AUTOSAR XML (schema 4-2-2)
package /STELLANTIS/EPT/ASWCs
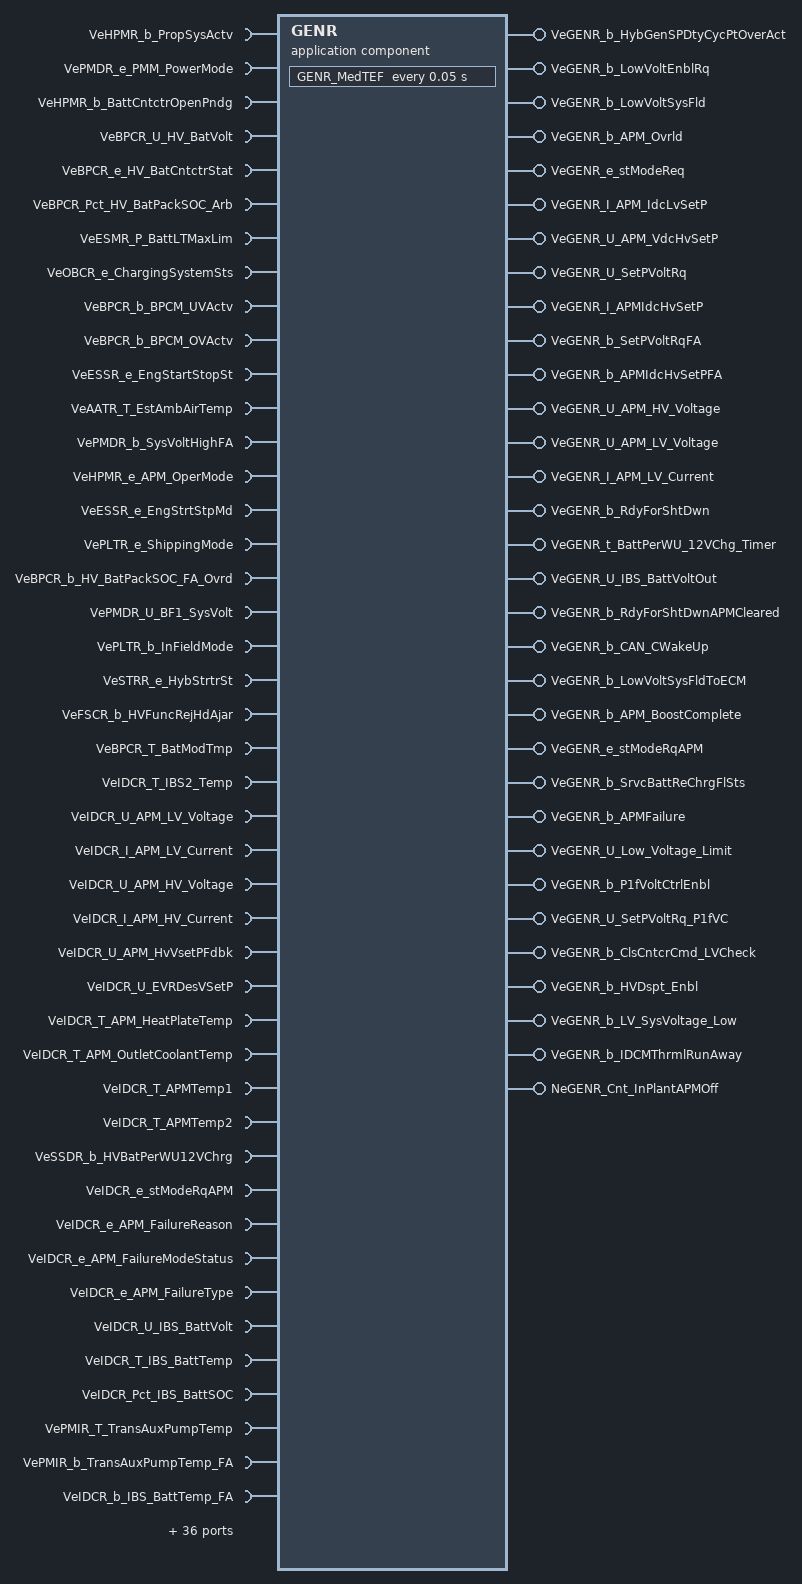
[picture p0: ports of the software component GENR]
  application sw component type GENR
    79 x require port:
      VeHPMR_b_PropSysActv: nonqueued-receiver-com-spec{data-element=Value, init-value=0}, required-interface=VeHPMR_b_PropSysActv
      VePMDR_e_PMM_PowerMode: nonqueued-receiver-com-spec{data-element=Value, init-value=CePMDR_e_PowerMode_Off}, required-interface=VePMDR_e_PMM_PowerMode
      VeHPMR_b_BattCntctrOpenPndg: nonqueued-receiver-com-spec{data-element=Value, init-value=0}, required-interface=VeHPMR_b_BattCntctrOpenPndg
      VeBPCR_U_HV_BatVolt: nonqueued-receiver-com-spec{data-element=Value, init-value=0}, required-interface=VeBPCR_U_HV_BatVolt
      VeBPCR_e_HV_BatCntctrStat: nonqueued-receiver-com-spec{data-element=Value, init-value=CeHVTR_e_Open}, required-interface=VeBPCR_e_HV_BatCntctrStat
      VeBPCR_Pct_HV_BatPackSOC_Arb: nonqueued-receiver-com-spec{data-element=Value, init-value=0}, required-interface=VeBPCR_Pct_HV_BatPackSOC_Arb
      VeESMR_P_BattLTMaxLim: nonqueued-receiver-com-spec{data-element=Value, init-value=0}, required-interface=VeESMR_P_BattLTMaxLim
      VeOBCR_e_ChargingSystemSts: nonqueued-receiver-com-spec{data-element=Value, init-value=CeOBCR_e_NotCharging}, required-interface=VeOBCR_e_ChargingSystemSts
      VeBPCR_b_BPCM_UVActv: nonqueued-receiver-com-spec{data-element=Value, init-value=0}, required-interface=VeBPCR_b_BPCM_UVActv
      VeBPCR_b_BPCM_OVActv: nonqueued-receiver-com-spec{data-element=Value, init-value=0}, required-interface=VeBPCR_b_BPCM_OVActv
      VeESSR_e_EngStartStopSt: nonqueued-receiver-com-spec{data-element=Value, init-value=CeESSR_e_EngOff}, required-interface=VeESSR_e_EngStartStopSt
      VeAATR_T_EstAmbAirTemp: nonqueued-receiver-com-spec{data-element=Value, init-value=0}, required-interface=VeAATR_T_EstAmbAirTemp
      VePMDR_b_SysVoltHighFA: nonqueued-receiver-com-spec{data-element=Value, init-value=0}, required-interface=VePMDR_b_SysVoltHighFA
      VeHPMR_e_APM_OperMode: nonqueued-receiver-com-spec{data-element=Value, init-value=CeHPMR_e_Idle}, required-interface=VeHPMR_e_APM_OperMode
      VeESSR_e_EngStrtStpMd: nonqueued-receiver-com-spec{data-element=Value, init-value=CeESSR_e_Stop}, required-interface=VeESSR_e_EngStrtStpMd
      VePLTR_e_ShippingMode: nonqueued-receiver-com-spec{data-element=Value, init-value=CePLTR_e_ShipingMode_CUST_MD}, required-interface=VePLTR_e_ShippingMode
      VeBPCR_b_HV_BatPackSOC_FA_Ovrd: nonqueued-receiver-com-spec{data-element=Value, init-value=0}, required-interface=VeBPCR_b_HV_BatPackSOC_FA_Ovrd
      VePMDR_U_BF1_SysVolt: nonqueued-receiver-com-spec{data-element=Value, init-value=0}, required-interface=VePMDR_U_BF1_SysVolt
      VePLTR_b_InFieldMode: nonqueued-receiver-com-spec{data-element=Value, init-value=0}, required-interface=VePLTR_b_InFieldMode
      VeSTRR_e_HybStrtrSt: nonqueued-receiver-com-spec{data-element=Value, init-value=CeSTRR_e_KeyOffSt}, required-interface=VeSTRR_e_HybStrtrSt
      VeFSCR_b_HVFuncRejHdAjar: nonqueued-receiver-com-spec{data-element=Value, init-value=0}, required-interface=VeFSCR_b_HVFuncRejHdAjar
      VeBPCR_T_BatModTmp: nonqueued-receiver-com-spec{data-element=Value, init-value=0}, required-interface=VeBPCR_T_BatModTmp
      VeIDCR_T_IBS2_Temp: nonqueued-receiver-com-spec{data-element=Value, init-value=0}, required-interface=VeIDCR_T_IBS2_Temp
      VeIDCR_U_APM_LV_Voltage: nonqueued-receiver-com-spec{data-element=Value, init-value=0}, required-interface=VeIDCR_U_APM_LV_Voltage
      VeIDCR_I_APM_LV_Current: nonqueued-receiver-com-spec{data-element=Value, init-value=0}, required-interface=VeIDCR_I_APM_LV_Current
      VeIDCR_U_APM_HV_Voltage: nonqueued-receiver-com-spec{data-element=Value, init-value=0}, required-interface=VeIDCR_U_APM_HV_Voltage
      VeIDCR_I_APM_HV_Current: nonqueued-receiver-com-spec{data-element=Value, init-value=0}, required-interface=VeIDCR_I_APM_HV_Current
      VeIDCR_U_APM_HvVsetPFdbk: nonqueued-receiver-com-spec{data-element=Value, init-value=0}, required-interface=VeIDCR_U_APM_HvVsetPFdbk
      VeIDCR_U_EVRDesVSetP: nonqueued-receiver-com-spec{data-element=Value, init-value=0}, required-interface=VeIDCR_U_EVRDesVSetP
      VeIDCR_T_APM_HeatPlateTemp: nonqueued-receiver-com-spec{data-element=Value, init-value=0}, required-interface=VeIDCR_T_APM_HeatPlateTemp
      VeIDCR_T_APM_OutletCoolantTemp: nonqueued-receiver-com-spec{data-element=Value, init-value=0}, required-interface=VeIDCR_T_APM_OutletCoolantTemp
      VeIDCR_T_APMTemp1: nonqueued-receiver-com-spec{data-element=Value, init-value=0}, required-interface=VeIDCR_T_APMTemp1
      VeIDCR_T_APMTemp2: nonqueued-receiver-com-spec{data-element=Value, init-value=0}, required-interface=VeIDCR_T_APMTemp2
      VeSSDR_b_HVBatPerWU12VChrg: nonqueued-receiver-com-spec{data-element=Value, init-value=0}, required-interface=VeSSDR_b_HVBatPerWU12VChrg
      VeIDCR_e_stModeRqAPM: nonqueued-receiver-com-spec{data-element=Value, init-value=CeGENR_e_Default}, required-interface=VeIDCR_e_stModeRqAPM
      VeIDCR_e_APM_FailureReason: nonqueued-receiver-com-spec{data-element=Value, init-value=CeGENR_e_NoFailure}, required-interface=VeIDCR_e_APM_FailureReason
      VeIDCR_e_APM_FailureModeStatus: nonqueued-receiver-com-spec{data-element=Value, init-value=CeGENR_e_NoFailure}, required-interface=VeIDCR_e_APM_FailureModeStatus
      VeIDCR_e_APM_FailureType: nonqueued-receiver-com-spec{data-element=Value, init-value=CeGENR_e_FailureType_NoFailure}, required-interface=VeIDCR_e_APM_FailureType
      VeIDCR_U_IBS_BattVolt: nonqueued-receiver-com-spec{data-element=Value, init-value=0}, required-interface=VeIDCR_U_IBS_BattVolt
      VeIDCR_T_IBS_BattTemp: nonqueued-receiver-com-spec{data-element=Value, init-value=0}, required-interface=VeIDCR_T_IBS_BattTemp
      VeIDCR_Pct_IBS_BattSOC: nonqueued-receiver-com-spec{data-element=Value, init-value=0}, required-interface=VeIDCR_Pct_IBS_BattSOC
      VePMIR_T_TransAuxPumpTemp: nonqueued-receiver-com-spec{data-element=Value, init-value=0}, required-interface=VePMIR_T_TransAuxPumpTemp
      VePMIR_b_TransAuxPumpTemp_FA: nonqueued-receiver-com-spec{data-element=Value, init-value=0}, required-interface=VePMIR_b_TransAuxPumpTemp_FA
      VeIDCR_b_IBS_BattTemp_FA: nonqueued-receiver-com-spec{data-element=Value, init-value=0}, required-interface=VeIDCR_b_IBS_BattTemp_FA
      VeIDCR_e_IBS_BattTempFailSts: nonqueued-receiver-com-spec{data-element=Value, init-value=CeGENR_e_BattTempSts_Fail_NtPrsnt}, required-interface=VeIDCR_e_IBS_BattTempFailSts
      VeIDCR_b_IBS_BattTemp_SgnlRcvd: nonqueued-receiver-com-spec{data-element=Value, init-value=0}, required-interface=VeIDCR_b_IBS_BattTemp_SgnlRcvd
      VeIDCR_b_APM_HvVsetPFdbk_FA: nonqueued-receiver-com-spec{data-element=Value, init-value=0}, required-interface=VeIDCR_b_APM_HvVsetPFdbk_FA
      VeIDCR_b_IBS_BattSOC_FA: nonqueued-receiver-com-spec{data-element=Value, init-value=0}, required-interface=VeIDCR_b_IBS_BattSOC_FA
      VeIDCR_b_IBS_BattVolt_FA: nonqueued-receiver-com-spec{data-element=Value, init-value=0}, required-interface=VeIDCR_b_IBS_BattVolt_FA
      VeINVR_e_MtrA_InvrtrSt: nonqueued-receiver-com-spec{data-element=Value, init-value=CeINVR_e_NormalPowerStageOff}, required-interface=VeINVR_e_MtrA_InvrtrSt
      VeIDCR_e_DVC_APMSts: nonqueued-receiver-com-spec{data-element=Value, init-value=CeODCR_e_Return_ECU_Cntrl}, required-interface=VeIDCR_e_DVC_APMSts
      VeIDCR_y_APMSts: nonqueued-receiver-com-spec{data-element=Value, init-value=0}, required-interface=VeIDCR_y_APMSts
      VeIDCR_Pct_UtilPctOfDCDC: nonqueued-receiver-com-spec{data-element=Value, init-value=0}, required-interface=VeIDCR_Pct_UtilPctOfDCDC
      VeIDCR_e_APM_DeratingModeStatus: nonqueued-receiver-com-spec{data-element=Value, init-value=CeGENR_e_No_Derating}, required-interface=VeIDCR_e_APM_DeratingModeStatus
      VeIDCR_P_APM_OutputPwr: nonqueued-receiver-com-spec{data-element=Value, init-value=0}, required-interface=VeIDCR_P_APM_OutputPwr
      VeIDCR_P_APM_DeratePwr: nonqueued-receiver-com-spec{data-element=Value, init-value=0}, required-interface=VeIDCR_P_APM_DeratePwr
      VeIDCR_b_IBS_I_Batt_SgnlRcvd: nonqueued-receiver-com-spec{data-element=Value, init-value=0}, required-interface=VeIDCR_b_IBS_I_Batt_SgnlRcvd
      VeINVR_b_P1_CAN_COM_Error: nonqueued-receiver-com-spec{data-element=Value, init-value=0}, required-interface=VeINVR_b_P1_CAN_COM_Error
      VeBPCR_b_HVBatCntrWeld_ImpdOpn: nonqueued-receiver-com-spec{data-element=Value, init-value=0}, required-interface=VeBPCR_b_HVBatCntrWeld_ImpdOpn
      VeSRAR_b_OpnBattCntctr: nonqueued-receiver-com-spec{data-element=Value, init-value=0}, required-interface=VeSRAR_b_OpnBattCntctr
      VeIDCR_I_IBS_I_Converted: nonqueued-receiver-com-spec{data-element=Value, init-value=0}, required-interface=VeIDCR_I_IBS_I_Converted
      VeIDCR_b_IBS_I_Converted_FA: nonqueued-receiver-com-spec{data-element=Value, init-value=0}, required-interface=VeIDCR_b_IBS_I_Converted_FA
      VeFSCR_Pct_RadFanCmd: nonqueued-receiver-com-spec{data-element=Value, init-value=0}, required-interface=VeFSCR_Pct_RadFanCmd
      VeTAIR_Pct_FrtBlwrCmd: nonqueued-receiver-com-spec{data-element=Value, init-value=0}, required-interface=VeTAIR_Pct_FrtBlwrCmd
      VePMDR_U_BF2_SysVolt: nonqueued-receiver-com-spec{data-element=Value, init-value=0}, required-interface=VePMDR_U_BF2_SysVolt
      VeDMAB_y_StatusByte_InvData_APM: nonqueued-receiver-com-spec{data-element=Value, init-value=0}, required-interface=VeDMAB_y_StatusByte_InvData_APM
      VeDMAB_y_StatusByte_InvData_IDCM_CANC11: nonqueued-receiver-com-spec{data-element=Value, init-value=0}, required-interface=VeDMAB_y_StatusByte_InvData_IDCM_CANC11
      VeDMAB_y_StatusByte_InvData_IDCM: nonqueued-receiver-com-spec{data-element=Value, init-value=0}, required-interface=VeDMAB_y_StatusByte_InvData_IDCM
      VeDMAB_y_StatusByte_LosCommBECM_A: nonqueued-receiver-com-spec{data-element=Value, init-value=0}, required-interface=VeDMAB_y_StatusByte_LosCommBECM_A
      VeDMAB_y_StatusByte_LostCommBCM: nonqueued-receiver-com-spec{data-element=Value, init-value=0}, required-interface=VeDMAB_y_StatusByte_LostCommBCM
      VeDMAB_y_StatusByte_LostCommDCDC: nonqueued-receiver-com-spec{data-element=Value, init-value=0}, required-interface=VeDMAB_y_StatusByte_LostCommDCDC
      VeDMAB_y_StatusByte_LostCommIDCM: nonqueued-receiver-com-spec{data-element=Value, init-value=0}, required-interface=VeDMAB_y_StatusByte_LostCommIDCM
      VeDMAB_y_StatusByte_LostComm_IDCM_CANC11: nonqueued-receiver-com-spec{data-element=Value, init-value=0}, required-interface=VeDMAB_y_StatusByte_LostComm_IDCM_CANC11
      VeDMAB_y_StatusByte_HiSpdCANCommBus: nonqueued-receiver-com-spec{data-element=Value, init-value=0}, required-interface=VeDMAB_y_StatusByte_HiSpdCANCommBus
      VeDMAB_y_StatusByte_CommBus_B_Off: nonqueued-receiver-com-spec{data-element=Value, init-value=0}, required-interface=VeDMAB_y_StatusByte_CommBus_B_Off
      VeDMAB_y_StatusByte_InvData_SGCM: nonqueued-receiver-com-spec{data-element=Value, init-value=0}, required-interface=VeDMAB_y_StatusByte_InvData_SGCM
      VeDMAB_y_StatusByte_LostCommSGCM: nonqueued-receiver-com-spec{data-element=Value, init-value=0}, required-interface=VeDMAB_y_StatusByte_LostCommSGCM
      VeHVTR_I_StringCurrent_Arb: nonqueued-receiver-com-spec{data-element=Value, init-value=0}, required-interface=VeHVTR_I_StringCurrent_Arb
      VeDMAB_y_StatusByte_LostComm_IDCM_ePT2: nonqueued-receiver-com-spec{data-element=Value, init-value=0}, required-interface=VeDMAB_y_StatusByte_LostComm_IDCM_ePT2
    31 x provide port:
      VeGENR_b_HybGenSPDtyCycPtOverAct: nonqueued-sender-com-spec{data-element=Value, init-value=0}, provided-interface=VeGENR_b_HybGenSPDtyCycPtOverAct
      VeGENR_b_LowVoltEnblRq: nonqueued-sender-com-spec{data-element=Value, init-value=0}, provided-interface=VeGENR_b_LowVoltEnblRq
      VeGENR_b_LowVoltSysFld: nonqueued-sender-com-spec{data-element=Value, init-value=0}, provided-interface=VeGENR_b_LowVoltSysFld
      VeGENR_b_APM_Ovrld: nonqueued-sender-com-spec{data-element=Value, init-value=0}, provided-interface=VeGENR_b_APM_Ovrld
      VeGENR_e_stModeReq: nonqueued-sender-com-spec{data-element=Value, init-value=CeGENR_e_Default}, provided-interface=VeGENR_e_stModeReq
      VeGENR_I_APM_IdcLvSetP: nonqueued-sender-com-spec{data-element=Value, init-value=0}, provided-interface=VeGENR_I_APM_IdcLvSetP
      VeGENR_U_APM_VdcHvSetP: nonqueued-sender-com-spec{data-element=Value, init-value=0}, provided-interface=VeGENR_U_APM_VdcHvSetP
      VeGENR_U_SetPVoltRq: nonqueued-sender-com-spec{data-element=Value, init-value=0}, provided-interface=VeGENR_U_SetPVoltRq
      VeGENR_I_APMIdcHvSetP: nonqueued-sender-com-spec{data-element=Value, init-value=0}, provided-interface=VeGENR_I_APMIdcHvSetP
      VeGENR_b_SetPVoltRqFA: nonqueued-sender-com-spec{data-element=Value, init-value=0}, provided-interface=VeGENR_b_SetPVoltRqFA
      VeGENR_b_APMIdcHvSetPFA: nonqueued-sender-com-spec{data-element=Value, init-value=0}, provided-interface=VeGENR_b_APMIdcHvSetPFA
      VeGENR_U_APM_HV_Voltage: nonqueued-sender-com-spec{data-element=Value, init-value=0}, provided-interface=VeGENR_U_APM_HV_Voltage
      VeGENR_U_APM_LV_Voltage: nonqueued-sender-com-spec{data-element=Value, init-value=0}, provided-interface=VeGENR_U_APM_LV_Voltage
      VeGENR_I_APM_LV_Current: nonqueued-sender-com-spec{data-element=Value, init-value=0}, provided-interface=VeGENR_I_APM_LV_Current
      VeGENR_b_RdyForShtDwn: nonqueued-sender-com-spec{data-element=Value, init-value=0}, provided-interface=VeGENR_b_RdyForShtDwn
      VeGENR_t_BattPerWU_12VChg_Timer: nonqueued-sender-com-spec{data-element=Value, init-value=0}, provided-interface=VeGENR_t_BattPerWU_12VChg_Timer
      VeGENR_U_IBS_BattVoltOut: nonqueued-sender-com-spec{data-element=Value, init-value=0}, provided-interface=VeGENR_U_IBS_BattVoltOut
      VeGENR_b_RdyForShtDwnAPMCleared: nonqueued-sender-com-spec{data-element=Value, init-value=0}, provided-interface=VeGENR_b_RdyForShtDwnAPMCleared
      VeGENR_b_CAN_CWakeUp: nonqueued-sender-com-spec{data-element=Value, init-value=0}, provided-interface=VeGENR_b_CAN_CWakeUp
      VeGENR_b_LowVoltSysFldToECM: nonqueued-sender-com-spec{data-element=Value, init-value=0}, provided-interface=VeGENR_b_LowVoltSysFldToECM
      VeGENR_b_APM_BoostComplete: nonqueued-sender-com-spec{data-element=Value, init-value=0}, provided-interface=VeGENR_b_APM_BoostComplete
      VeGENR_e_stModeRqAPM: nonqueued-sender-com-spec{data-element=Value, init-value=CeGENR_e_Default}, provided-interface=VeGENR_e_stModeRqAPM
      VeGENR_b_SrvcBattReChrgFlSts: nonqueued-sender-com-spec{data-element=Value, init-value=0}, provided-interface=VeGENR_b_SrvcBattReChrgFlSts
      VeGENR_b_APMFailure: nonqueued-sender-com-spec{data-element=Value, init-value=0}, provided-interface=VeGENR_b_APMFailure
      VeGENR_U_Low_Voltage_Limit: nonqueued-sender-com-spec{data-element=Value, init-value=0}, provided-interface=VeGENR_U_Low_Voltage_Limit
      VeGENR_b_P1fVoltCtrlEnbl: nonqueued-sender-com-spec{data-element=Value, init-value=0}, provided-interface=VeGENR_b_P1fVoltCtrlEnbl
      VeGENR_U_SetPVoltRq_P1fVC: nonqueued-sender-com-spec{data-element=Value, init-value=0}, provided-interface=VeGENR_U_SetPVoltRq_P1fVC
      VeGENR_b_ClsCntcrCmd_LVCheck: nonqueued-sender-com-spec{data-element=Value, init-value=0}, provided-interface=VeGENR_b_ClsCntcrCmd_LVCheck
      VeGENR_b_HVDspt_Enbl: nonqueued-sender-com-spec{data-element=Value, init-value=0}, provided-interface=VeGENR_b_HVDspt_Enbl
      VeGENR_b_LV_SysVoltage_Low: nonqueued-sender-com-spec{data-element=Value, init-value=0}, provided-interface=VeGENR_b_LV_SysVoltage_Low
      VeGENR_b_IDCMThrmlRunAway: nonqueued-sender-com-spec{data-element=Value, init-value=0}, provided-interface=VeGENR_b_IDCMThrmlRunAway
    require port NeGENR_Cnt_InPlantAPMOff_Rx: nv-require-com-spec{init-value=0, variable=NeGENR_Cnt_InPlantAPMOff}, required-interface=NeGENR_Cnt_InPlantAPMOff
    provide port NeGENR_Cnt_InPlantAPMOff: nv-provide-com-spec{ram-block-init-value=0, variable=NeGENR_Cnt_InPlantAPMOff}, provided-interface=NeGENR_Cnt_InPlantAPMOff
    behavior IB_GENR: data-type-mapping=msADTtoIDTMapping, handle-termination-and-restart=NO-SUPPORT
      timing event Event_MedTEF: start-on-event=GENR_MedTEF, period=0.05
      init event Event_GENR_ac_Init: start-on-event=GENR_ac_Init
      init event Event_PwrOn: start-on-event=GENR_PwrOn
      init event Event_PwrOff: start-on-event=GENR_PwrOff
      4 x runnable:
        GENR_ac_Init
          data-send-points:
            access OUT_VeGENR_e_stModeReq_Value: accessed-variable=VeGENR_e_stModeReq.Value
            access OUT_VeGENR_e_stModeRqAPM_Value: accessed-variable=VeGENR_e_stModeRqAPM.Value
        GENR_MedTEF
          data-receive-point-by-arguments:
            78 x access:
              IN_VeAATR_T_EstAmbAirTemp_Value: accessed-variable=VeAATR_T_EstAmbAirTemp.Value
              IN_VeBPCR_Pct_HV_BatPackSOC_Arb_Value: accessed-variable=VeBPCR_Pct_HV_BatPackSOC_Arb.Value
              IN_VeBPCR_T_BatModTmp_Value: accessed-variable=VeBPCR_T_BatModTmp.Value
              IN_VeBPCR_U_HV_BatVolt_Value: accessed-variable=VeBPCR_U_HV_BatVolt.Value
              IN_VeBPCR_b_BPCM_OVActv_Value: accessed-variable=VeBPCR_b_BPCM_OVActv.Value
              IN_VeBPCR_b_BPCM_UVActv_Value: accessed-variable=VeBPCR_b_BPCM_UVActv.Value
              IN_VeBPCR_b_HVBatCntrWeld_ImpdOpn_Value: accessed-variable=VeBPCR_b_HVBatCntrWeld_ImpdOpn.Value
              IN_VeBPCR_b_HV_BatPackSOC_FA_Ovrd_Value: accessed-variable=VeBPCR_b_HV_BatPackSOC_FA_Ovrd.Value
              IN_VeBPCR_e_HV_BatCntctrStat_Value: accessed-variable=VeBPCR_e_HV_BatCntctrStat.Value
              IN_VeDMAB_y_StatusByte_CommBus_B_Off_Value: accessed-variable=VeDMAB_y_StatusByte_CommBus_B_Off.Value
              IN_VeDMAB_y_StatusByte_HiSpdCANCommBus_Value: accessed-variable=VeDMAB_y_StatusByte_HiSpdCANCommBus.Value
              IN_VeDMAB_y_StatusByte_InvData_APM_Value: accessed-variable=VeDMAB_y_StatusByte_InvData_APM.Value
              IN_VeDMAB_y_StatusByte_InvData_IDCM_Value: accessed-variable=VeDMAB_y_StatusByte_InvData_IDCM.Value
              IN_VeDMAB_y_StatusByte_InvData_IDCM_CANC11_Value: accessed-variable=VeDMAB_y_StatusByte_InvData_IDCM_CANC11.Value
              IN_VeDMAB_y_StatusByte_InvData_SGCM_Value: accessed-variable=VeDMAB_y_StatusByte_InvData_SGCM.Value
              IN_VeDMAB_y_StatusByte_LosCommBECM_A_Value: accessed-variable=VeDMAB_y_StatusByte_LosCommBECM_A.Value
              IN_VeDMAB_y_StatusByte_LostCommBCM_Value: accessed-variable=VeDMAB_y_StatusByte_LostCommBCM.Value
              IN_VeDMAB_y_StatusByte_LostCommDCDC_Value: accessed-variable=VeDMAB_y_StatusByte_LostCommDCDC.Value
              IN_VeDMAB_y_StatusByte_LostCommIDCM_Value: accessed-variable=VeDMAB_y_StatusByte_LostCommIDCM.Value
              IN_VeDMAB_y_StatusByte_LostCommSGCM_Value: accessed-variable=VeDMAB_y_StatusByte_LostCommSGCM.Value
              IN_VeDMAB_y_StatusByte_LostComm_IDCM_CANC11_Value: accessed-variable=VeDMAB_y_StatusByte_LostComm_IDCM_CANC11.Value
              IN_VeDMAB_y_StatusByte_LostComm_IDCM_ePT2_Value: accessed-variable=VeDMAB_y_StatusByte_LostComm_IDCM_ePT2.Value
              IN_VeESMR_P_BattLTMaxLim_Value: accessed-variable=VeESMR_P_BattLTMaxLim.Value
              IN_VeESSR_e_EngStartStopSt_Value: accessed-variable=VeESSR_e_EngStartStopSt.Value
              IN_VeESSR_e_EngStrtStpMd_Value: accessed-variable=VeESSR_e_EngStrtStpMd.Value
              IN_VeFSCR_Pct_RadFanCmd_Value: accessed-variable=VeFSCR_Pct_RadFanCmd.Value
              IN_VeFSCR_b_HVFuncRejHdAjar_Value: accessed-variable=VeFSCR_b_HVFuncRejHdAjar.Value
              IN_VeHPMR_b_BattCntctrOpenPndg_Value: accessed-variable=VeHPMR_b_BattCntctrOpenPndg.Value
              IN_VeHPMR_b_PropSysActv_Value: accessed-variable=VeHPMR_b_PropSysActv.Value
              IN_VeHPMR_e_APM_OperMode_Value: accessed-variable=VeHPMR_e_APM_OperMode.Value
              IN_VeHVTR_I_StringCurrent_Arb_Value: accessed-variable=VeHVTR_I_StringCurrent_Arb.Value
              IN_VeIDCR_I_APM_HV_Current_Value: accessed-variable=VeIDCR_I_APM_HV_Current.Value
              IN_VeIDCR_I_APM_LV_Current_Value: accessed-variable=VeIDCR_I_APM_LV_Current.Value
              IN_VeIDCR_I_IBS_I_Converted_Value: accessed-variable=VeIDCR_I_IBS_I_Converted.Value
              IN_VeIDCR_P_APM_DeratePwr_Value: accessed-variable=VeIDCR_P_APM_DeratePwr.Value
              IN_VeIDCR_P_APM_OutputPwr_Value: accessed-variable=VeIDCR_P_APM_OutputPwr.Value
              IN_VeIDCR_Pct_IBS_BattSOC_Value: accessed-variable=VeIDCR_Pct_IBS_BattSOC.Value
              IN_VeIDCR_Pct_UtilPctOfDCDC_Value: accessed-variable=VeIDCR_Pct_UtilPctOfDCDC.Value
              IN_VeIDCR_T_APMTemp1_Value: accessed-variable=VeIDCR_T_APMTemp1.Value
              IN_VeIDCR_T_APMTemp2_Value: accessed-variable=VeIDCR_T_APMTemp2.Value
              IN_VeIDCR_T_APM_HeatPlateTemp_Value: accessed-variable=VeIDCR_T_APM_HeatPlateTemp.Value
              IN_VeIDCR_T_APM_OutletCoolantTemp_Value: accessed-variable=VeIDCR_T_APM_OutletCoolantTemp.Value
              IN_VeIDCR_T_IBS2_Temp_Value: accessed-variable=VeIDCR_T_IBS2_Temp.Value
              IN_VeIDCR_T_IBS_BattTemp_Value: accessed-variable=VeIDCR_T_IBS_BattTemp.Value
              IN_VeIDCR_U_APM_HV_Voltage_Value: accessed-variable=VeIDCR_U_APM_HV_Voltage.Value
              IN_VeIDCR_U_APM_HvVsetPFdbk_Value: accessed-variable=VeIDCR_U_APM_HvVsetPFdbk.Value
              IN_VeIDCR_U_APM_LV_Voltage_Value: accessed-variable=VeIDCR_U_APM_LV_Voltage.Value
              IN_VeIDCR_U_EVRDesVSetP_Value: accessed-variable=VeIDCR_U_EVRDesVSetP.Value
              IN_VeIDCR_U_IBS_BattVolt_Value: accessed-variable=VeIDCR_U_IBS_BattVolt.Value
              IN_VeIDCR_b_IBS_BattSOC_FA_Value: accessed-variable=VeIDCR_b_IBS_BattSOC_FA.Value
              IN_VeIDCR_b_IBS_BattTemp_FA_Value: accessed-variable=VeIDCR_b_IBS_BattTemp_FA.Value
              IN_VeIDCR_b_IBS_BattTemp_SgnlRcvd_Value: accessed-variable=VeIDCR_b_IBS_BattTemp_SgnlRcvd.Value
              IN_VeIDCR_b_IBS_BattVolt_FA_Value: accessed-variable=VeIDCR_b_IBS_BattVolt_FA.Value
              IN_VeIDCR_b_IBS_I_Batt_SgnlRcvd_Value: accessed-variable=VeIDCR_b_IBS_I_Batt_SgnlRcvd.Value
              IN_VeIDCR_b_IBS_I_Converted_FA_Value: accessed-variable=VeIDCR_b_IBS_I_Converted_FA.Value
              IN_VeIDCR_e_APM_DeratingModeStatus_Value: accessed-variable=VeIDCR_e_APM_DeratingModeStatus.Value
              IN_VeIDCR_e_APM_FailureModeStatus_Value: accessed-variable=VeIDCR_e_APM_FailureModeStatus.Value
              IN_VeIDCR_e_APM_FailureReason_Value: accessed-variable=VeIDCR_e_APM_FailureReason.Value
              IN_VeIDCR_e_APM_FailureType_Value: accessed-variable=VeIDCR_e_APM_FailureType.Value
              IN_VeIDCR_e_DVC_APMSts_Value: accessed-variable=VeIDCR_e_DVC_APMSts.Value
              IN_VeIDCR_e_IBS_BattTempFailSts_Value: accessed-variable=VeIDCR_e_IBS_BattTempFailSts.Value
              IN_VeIDCR_e_stModeRqAPM_Value: accessed-variable=VeIDCR_e_stModeRqAPM.Value
              IN_VeIDCR_y_APMSts_Value: accessed-variable=VeIDCR_y_APMSts.Value
              IN_VeINVR_b_P1_CAN_COM_Error_Value: accessed-variable=VeINVR_b_P1_CAN_COM_Error.Value
              IN_VeINVR_e_MtrA_InvrtrSt_Value: accessed-variable=VeINVR_e_MtrA_InvrtrSt.Value
              IN_VeOBCR_e_ChargingSystemSts_Value: accessed-variable=VeOBCR_e_ChargingSystemSts.Value
              IN_VePLTR_b_InFieldMode_Value: accessed-variable=VePLTR_b_InFieldMode.Value
              IN_VePLTR_e_ShippingMode_Value: accessed-variable=VePLTR_e_ShippingMode.Value
              IN_VePMDR_U_BF1_SysVolt_Value: accessed-variable=VePMDR_U_BF1_SysVolt.Value
              IN_VePMDR_U_BF2_SysVolt_Value: accessed-variable=VePMDR_U_BF2_SysVolt.Value
              IN_VePMDR_b_SysVoltHighFA_Value: accessed-variable=VePMDR_b_SysVoltHighFA.Value
              IN_VePMDR_e_PMM_PowerMode_Value: accessed-variable=VePMDR_e_PMM_PowerMode.Value
              IN_VePMIR_T_TransAuxPumpTemp_Value: accessed-variable=VePMIR_T_TransAuxPumpTemp.Value
              IN_VePMIR_b_TransAuxPumpTemp_FA_Value: accessed-variable=VePMIR_b_TransAuxPumpTemp_FA.Value
              IN_VeSRAR_b_OpnBattCntctr_Value: accessed-variable=VeSRAR_b_OpnBattCntctr.Value
              IN_VeSSDR_b_HVBatPerWU12VChrg_Value: accessed-variable=VeSSDR_b_HVBatPerWU12VChrg.Value
              IN_VeSTRR_e_HybStrtrSt_Value: accessed-variable=VeSTRR_e_HybStrtrSt.Value
              IN_VeTAIR_Pct_FrtBlwrCmd_Value: accessed-variable=VeTAIR_Pct_FrtBlwrCmd.Value
          data-send-points:
            31 x access:
              OUT_VeGENR_b_HybGenSPDtyCycPtOverAct_Value: accessed-variable=VeGENR_b_HybGenSPDtyCycPtOverAct.Value
              OUT_VeGENR_b_LowVoltEnblRq_Value: accessed-variable=VeGENR_b_LowVoltEnblRq.Value
              OUT_VeGENR_b_LowVoltSysFld_Value: accessed-variable=VeGENR_b_LowVoltSysFld.Value
              OUT_VeGENR_b_APM_Ovrld_Value: accessed-variable=VeGENR_b_APM_Ovrld.Value
              OUT_VeGENR_e_stModeReq_Value: accessed-variable=VeGENR_e_stModeReq.Value
              OUT_VeGENR_I_APM_IdcLvSetP_Value: accessed-variable=VeGENR_I_APM_IdcLvSetP.Value
              OUT_VeGENR_U_APM_VdcHvSetP_Value: accessed-variable=VeGENR_U_APM_VdcHvSetP.Value
              OUT_VeGENR_U_SetPVoltRq_Value: accessed-variable=VeGENR_U_SetPVoltRq.Value
              OUT_VeGENR_I_APMIdcHvSetP_Value: accessed-variable=VeGENR_I_APMIdcHvSetP.Value
              OUT_VeGENR_b_SetPVoltRqFA_Value: accessed-variable=VeGENR_b_SetPVoltRqFA.Value
              OUT_VeGENR_b_APMIdcHvSetPFA_Value: accessed-variable=VeGENR_b_APMIdcHvSetPFA.Value
              OUT_VeGENR_U_APM_HV_Voltage_Value: accessed-variable=VeGENR_U_APM_HV_Voltage.Value
              OUT_VeGENR_U_APM_LV_Voltage_Value: accessed-variable=VeGENR_U_APM_LV_Voltage.Value
              OUT_VeGENR_I_APM_LV_Current_Value: accessed-variable=VeGENR_I_APM_LV_Current.Value
              OUT_VeGENR_b_RdyForShtDwn_Value: accessed-variable=VeGENR_b_RdyForShtDwn.Value
              OUT_VeGENR_t_BattPerWU_12VChg_Timer_Value: accessed-variable=VeGENR_t_BattPerWU_12VChg_Timer.Value
              OUT_VeGENR_U_IBS_BattVoltOut_Value: accessed-variable=VeGENR_U_IBS_BattVoltOut.Value
              OUT_VeGENR_b_RdyForShtDwnAPMCleared_Value: accessed-variable=VeGENR_b_RdyForShtDwnAPMCleared.Value
              OUT_VeGENR_b_CAN_CWakeUp_Value: accessed-variable=VeGENR_b_CAN_CWakeUp.Value
              OUT_VeGENR_b_LowVoltSysFldToECM_Value: accessed-variable=VeGENR_b_LowVoltSysFldToECM.Value
              OUT_VeGENR_b_APM_BoostComplete_Value: accessed-variable=VeGENR_b_APM_BoostComplete.Value
              OUT_VeGENR_e_stModeRqAPM_Value: accessed-variable=VeGENR_e_stModeRqAPM.Value
              OUT_VeGENR_b_SrvcBattReChrgFlSts_Value: accessed-variable=VeGENR_b_SrvcBattReChrgFlSts.Value
              OUT_VeGENR_b_APMFailure_Value: accessed-variable=VeGENR_b_APMFailure.Value
              OUT_VeGENR_U_Low_Voltage_Limit_Value: accessed-variable=VeGENR_U_Low_Voltage_Limit.Value
              OUT_VeGENR_b_P1fVoltCtrlEnbl_Value: accessed-variable=VeGENR_b_P1fVoltCtrlEnbl.Value
              OUT_VeGENR_U_SetPVoltRq_P1fVC_Value: accessed-variable=VeGENR_U_SetPVoltRq_P1fVC.Value
              OUT_VeGENR_b_ClsCntcrCmd_LVCheck_Value: accessed-variable=VeGENR_b_ClsCntcrCmd_LVCheck.Value
              OUT_VeGENR_b_HVDspt_Enbl_Value: accessed-variable=VeGENR_b_HVDspt_Enbl.Value
              OUT_VeGENR_b_LV_SysVoltage_Low_Value: accessed-variable=VeGENR_b_LV_SysVoltage_Low.Value
              OUT_VeGENR_b_IDCMThrmlRunAway_Value: accessed-variable=VeGENR_b_IDCMThrmlRunAway.Value
        GENR_PwrOn
          data-receive-point-by-arguments:
            access IN_NeGENR_Cnt_InPlantAPMOff_Rx_NeGENR_Cnt_InPlantAPMOff: accessed-variable=NeGENR_Cnt_InPlantAPMOff_Rx.NeGENR_Cnt_InPlantAPMOff
          data-send-points:
            31 x access:
              OUT_VeGENR_b_HybGenSPDtyCycPtOverAct_Value: accessed-variable=VeGENR_b_HybGenSPDtyCycPtOverAct.Value
              OUT_VeGENR_b_LowVoltEnblRq_Value: accessed-variable=VeGENR_b_LowVoltEnblRq.Value
              OUT_VeGENR_b_LowVoltSysFld_Value: accessed-variable=VeGENR_b_LowVoltSysFld.Value
              OUT_VeGENR_b_APM_Ovrld_Value: accessed-variable=VeGENR_b_APM_Ovrld.Value
              OUT_VeGENR_e_stModeReq_Value: accessed-variable=VeGENR_e_stModeReq.Value
              OUT_VeGENR_I_APM_IdcLvSetP_Value: accessed-variable=VeGENR_I_APM_IdcLvSetP.Value
              OUT_VeGENR_U_APM_VdcHvSetP_Value: accessed-variable=VeGENR_U_APM_VdcHvSetP.Value
              OUT_VeGENR_U_SetPVoltRq_Value: accessed-variable=VeGENR_U_SetPVoltRq.Value
              OUT_VeGENR_I_APMIdcHvSetP_Value: accessed-variable=VeGENR_I_APMIdcHvSetP.Value
              OUT_VeGENR_b_SetPVoltRqFA_Value: accessed-variable=VeGENR_b_SetPVoltRqFA.Value
              OUT_VeGENR_b_APMIdcHvSetPFA_Value: accessed-variable=VeGENR_b_APMIdcHvSetPFA.Value
              OUT_VeGENR_U_APM_HV_Voltage_Value: accessed-variable=VeGENR_U_APM_HV_Voltage.Value
              OUT_VeGENR_U_APM_LV_Voltage_Value: accessed-variable=VeGENR_U_APM_LV_Voltage.Value
              OUT_VeGENR_I_APM_LV_Current_Value: accessed-variable=VeGENR_I_APM_LV_Current.Value
              OUT_VeGENR_b_RdyForShtDwn_Value: accessed-variable=VeGENR_b_RdyForShtDwn.Value
              OUT_VeGENR_t_BattPerWU_12VChg_Timer_Value: accessed-variable=VeGENR_t_BattPerWU_12VChg_Timer.Value
              OUT_VeGENR_U_IBS_BattVoltOut_Value: accessed-variable=VeGENR_U_IBS_BattVoltOut.Value
              OUT_VeGENR_b_RdyForShtDwnAPMCleared_Value: accessed-variable=VeGENR_b_RdyForShtDwnAPMCleared.Value
              OUT_VeGENR_b_CAN_CWakeUp_Value: accessed-variable=VeGENR_b_CAN_CWakeUp.Value
              OUT_VeGENR_b_LowVoltSysFldToECM_Value: accessed-variable=VeGENR_b_LowVoltSysFldToECM.Value
              OUT_VeGENR_b_APM_BoostComplete_Value: accessed-variable=VeGENR_b_APM_BoostComplete.Value
              OUT_VeGENR_e_stModeRqAPM_Value: accessed-variable=VeGENR_e_stModeRqAPM.Value
              OUT_VeGENR_b_SrvcBattReChrgFlSts_Value: accessed-variable=VeGENR_b_SrvcBattReChrgFlSts.Value
              OUT_VeGENR_b_APMFailure_Value: accessed-variable=VeGENR_b_APMFailure.Value
              OUT_VeGENR_U_Low_Voltage_Limit_Value: accessed-variable=VeGENR_U_Low_Voltage_Limit.Value
              OUT_VeGENR_b_P1fVoltCtrlEnbl_Value: accessed-variable=VeGENR_b_P1fVoltCtrlEnbl.Value
              OUT_VeGENR_U_SetPVoltRq_P1fVC_Value: accessed-variable=VeGENR_U_SetPVoltRq_P1fVC.Value
              OUT_VeGENR_b_ClsCntcrCmd_LVCheck_Value: accessed-variable=VeGENR_b_ClsCntcrCmd_LVCheck.Value
              OUT_VeGENR_b_HVDspt_Enbl_Value: accessed-variable=VeGENR_b_HVDspt_Enbl.Value
              OUT_VeGENR_b_LV_SysVoltage_Low_Value: accessed-variable=VeGENR_b_LV_SysVoltage_Low.Value
              OUT_VeGENR_b_IDCMThrmlRunAway_Value: accessed-variable=VeGENR_b_IDCMThrmlRunAway.Value
        GENR_PwrOff
          data-send-points:
            access OUT_NeGENR_Cnt_InPlantAPMOff_NeGENR_Cnt_InPlantAPMOff: accessed-variable=NeGENR_Cnt_InPlantAPMOff.NeGENR_Cnt_InPlantAPMOff
      variation point proxy Variant_GENR_1: category=CONDITION, condition-access=0
